# rCSL_emifb_001 register map
Vendor: Texas Instruments
Peripheral module from a debugger description file (folder c674x).
Registers are 32-bit, access not given, reset 0x0 unless marked. A register's access mark holds for its fields unless they carry their own. Offsets are as the file gives them; lines under a group give offsets from that group; [hi:lo] are bit positions; {n}, {i} and the like mark numbered series; 'fields as' and 'values as' point back to an identical list; <NAME> marks a mode.

## EMIFB — This module acts as interface between CPU and SDR SDRAM
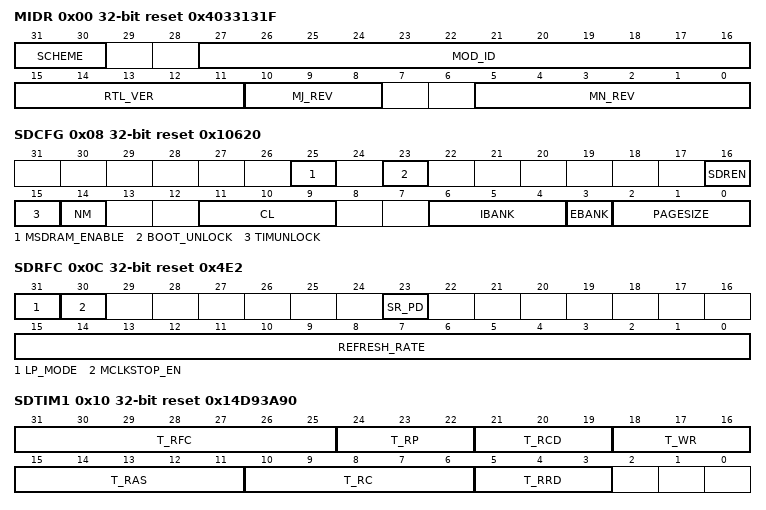
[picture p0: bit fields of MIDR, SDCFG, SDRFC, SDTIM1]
0x00 MIDR reset 0x4033131F — Read only ID register for EMIFB
  [31:30] SCHEME ro — Used to distinguish between old and current schemes
  [27:16] MOD_ID ro — EMIFB module ID
  [15:11] RTL_VER ro — RTL version
  [10:8] MJ_REV ro — Major revision
  [5:0] MN_REV ro — Minor revision
0x08 SDCFG reset 0x10620 — The SDRAM Configuration Register (SDCR) is used to configure various parameters of the SDRAM controller such as the number of internal banks, the internal page size, and the CAS latency to match those of the attached SDRAM device.
  [25] MSDRAM_ENABLE rw — Mobile SDRAM Enable. This bit is writeable only when the BTUNLOCK bit is unlocked. For mobile SDR SDRAM, this bit is only valid when SDREN is set to 1.
    0=MSDR_DIS (When SDREN=1, and this bit is zero, mobile SDR is not enabled.); 1=MSDR_EN (When SDREN=1, and this bit is 1, mobile SDR is enabled.)
  [23] BOOT_UNLOCK rw — Boot unlock. Set to 1 to change the values of the fields that are affected by the BTUNLOCK bit.
    0=BTUN_NOSET (The SDREN bit in this register may not be changed.); 1=BTUN_SET (The SDREN bit in this register may be changed.)
  [16] SDREN rw — SDRAM Enable. Active high bit which enables the SDRAM mode of the EMIF controller. This bit is writeable only when the BTUNLOCK bit is unlocked.
    0=SDR_DISABLE (SDRAM initialization and refreshes disabled, but SDRAM write/read transactions allowed. This bit must not be set to 0 when EMIF is in Self Refresh state.); 1=SDR_ENABLE (SDRAM fully enabled.)
  [15] TIMUNLOCK rw — Timing unlock. Controls the write permission settings for the SDRAM Timing 1 Register and SDRAM Timing 2 Register
    0=TMUN_NOSET (CL in this Register and Register fields in the SDRAM timing 1 register (SDTIMR1) and the SDRAM timing 2 register (SDTIMR2) may not be changed.); 1=TMUN_SET (CL in this Register and Register fields in the SDRAM timing 1 register (SDTIMR1) and the SDRAM timing 2 register (SDTIMR2) may be changed.)
  [14] NM rw — SDRAM data bus width. A write to this field will cause the EMIF to start the SDRAM initialization sequence.
    0=32BIT_SDR (32-bit SDR SDRAM); 1=16BIT_SDR (16-bit SDR SDRAM)
  [11:9] CL rw — CAS latency. A write to this field will cause the EMIF to start the SDRAM initialization sequence. This field is writeable only when the TMUNLOCK bit is unlocked.
  [6:4] IBANK rw — Internal SDRAM Bank setup. Defines number of banks inside connected SDRAM devices. A write to this field will cause the EMIF to start the SDRAM initialization sequence.
  [3] EBANK rw — External chip select setup. Defines whether SDRAM accesses will use 1 or 2 chip select lines. A write to this field will cause the EMIF to start the SDRAM initialization sequence.
    0=CS0 (Use EMIF_CS[0] for all SDRAM accesses.); 1=CS0_AND_CS1 (Use EMIF_CS[0] and EMIF_CS[1] for SDRAM accesses.)
  [2:0] PAGESIZE rw — Page Size. Defines the internal page size of connected SDRAM devices. A write to this field will cause the EMIF to start the SDRAM initialization sequence.
0x0C SDRFC reset 0x4E2 — SDRAM Refresh Control Register
  [31] LP_MODE rw — Low Power mode enable. Writing a 1 to this bit will cause connected SDRAM devices to be place into either Self Refresh or Powerdown mode. The value of SR_PD bit will decide which mode is chosen.
    0=LPMODE (SDRAM placed in self refresh /power down mode depending on the value of SR_PD bit.); 1=NO_LPMODE (SDRAM is NOT to be placed in self refresh/power down mode.)
  [30] MCLKSTOP_EN rw — mclk Stop Enable. Writing a 1 to this bit enables mclk stopping
    0=MCLKSTOP_DIS (mclk stopping disable); 1=MCLKSTOP_EN (mclk stopping enable)
  [23] SR_PD rw — Self Refresh or Powerdown select. Set this bit to 1 to cause connected SDRAM devices to be placed into Powerdown mode. Set this bit to 0 to cause connected SDRAM devices to be placed into Self Refresh mode. This bit is ignored when lp_mode bit is set to 0.
    0=SELF_REFRESH (Connected SDRAM devices placed in self refresh mode); 1=POWER_DOWN (Connected SDRAM devices placed in power down mode)
  [15:0] REFRESH_RATE rw — Refresh Rate. Defines the rate at which connected SDRAM devices will be refreshed.SDRAM refresh rate = EMIFB rate / RR where EMIFB rate is equal to EMIFB SDRAM clock rate. Writing a value < 0x0100 to this field will cause it to be loaded with (2 * t_rfc)+1 value from SDRAM Timing 1 register. The required refresh rate is derived from the SDRAM device data sheet.
0x10 SDTIM1 reset 0x14D93A90 — The SDRAM timing 1 register (SDTIMR1) configures the SDRAM memory controller to meet many of the AC timing specification of the SDRAM memory. The SDTIMR1 register is programmable only when the TMUNLOCK bit is set to 1 in the SDCR. Note that EMB_CLK is equal to the period of the EMB_CLK signal. See the SDRAM memory data sheet for information on the appropriate values to program each field.
  [31:25] T_RFC rw — Specifies the minimum number of EMB_CLK cycles from a refresh or load mode command to a refresh or activate command, minus 1. Corresponds to the trfc AC timing parameter in the SDRAM data sheet. Calculate by: T_RFC = (trfc/EMB_CLK) - 1
  [24:22] T_RP rw — Specifies the minimum number of EMB_CLK cycles from a precharge command to a refresh or activate command, minus 1. Corresponds to the trp AC timing parameter in the SDRAM data sheet. Calculate by: T_RP = (trp/EMB_CLK) - 1
  [21:19] T_RCD rw — Specifies the minimum number of EMB_CLK cycles from an activate command to a read or write command, minus 1. Corresponds to the trcd AC timing parameter in the SDRAM data sheet. Calculate by: T_RCD = (trcd/EMB_CLK) - 1
  [18:16] T_WR rw — Specifies the minimum number of EMB_CLK cycles from the last write transfer to a precharge command, minus 1. Corresponds to the twr AC timing parameter in the SDRAM data sheet. Calculate by: T_WR = (twr/EMB_CLK) - 1 When the value of this field is changed from its previous value, the initialization sequence will begin.
  [15:11] T_RAS rw — Specifies the minimum number of EMB_CLK cycles from an activate command to a precharge command, minus 1. Corresponds to the tras AC timing parameter in the SDRAM data sheet. Calculate by: T_RAS = (tras/EMB_CLK) - 1. T_RAS must be greater than or equal to T_RCD.
  [10:6] T_RC rw — Specifies the minimum number of EMB_CLK cycles from an activate command to an activate command, minus 1. Corresponds to the trc AC timing parameter in the SDRAM data sheet. Calculate by: T_RC = (trc/EMB_CLK) - 1
  [5:3] T_RRD rw — Specifies the minimum number of EMB_CLK cycles from an activate command to an activate command in a different bank, minus 1. Corresponds to the trrd AC timing parameter in the SDRAM data sheet. Calculate by: T_RRD = (trrd/EMB_CLK) - 1 Note: for an 8 bank SDRAM device this field must be equal to ((4 ´ tRRD) + (2 ´ tCK)) / (4 ´ tCK) - 1.
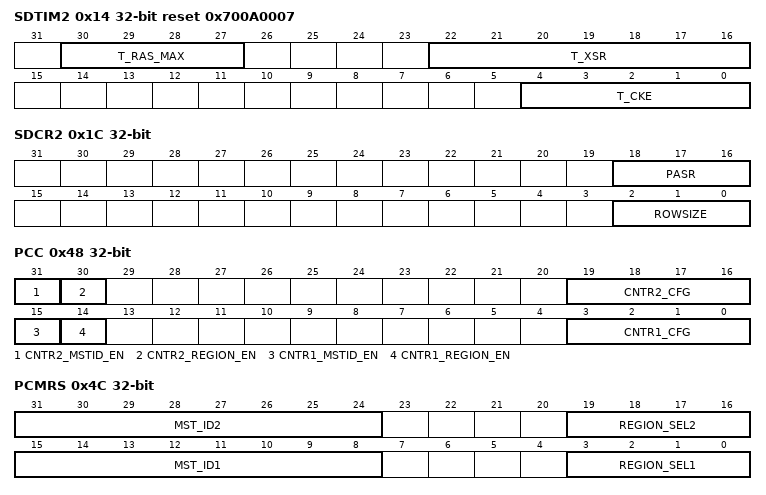
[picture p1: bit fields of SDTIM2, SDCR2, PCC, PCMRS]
0x14 SDTIM2 reset 0x700A0007 — Like the SDRAM timing 1 register (SDTIMR1), the SDRAM timing register 2 (SDTIMR2) also configures the SDRAM memory controller to meet the AC timing specification of the SDRAM memory. The SDTIMR2 register is programmable only when the TIMUNLOCK bit is set to 1 in the SDCR.See the SDRAM data sheet for information on the appropriate values to program each field.
  [30:27] T_RAS_MAX rw — Maximum number of refresh_rate intervals from Activate to Precharge command.
  [22:16] T_XSR rw — Minimum number of EMB_CLK cycles from Self-Refresh exit to any command other than a Read command, minus one. This field must satisfy tXSR for the SDRAM device. T_XSR = txsr*EMIFB_CLK -1
  [4:0] T_CKE rw — Minimum number of EMIFB_CLK cycles between EMB_CKE changes, minus one. This field must satisfy tRAS for the SDRAM device. T_CKE = tras *EMIFB_CLK-1
0x1C SDCR2 — SDRAM Config 2 Register
  [18:16] PASR rw — Partial Array Self Refresh. These bits get loaded into the Extended Mode Register of a mobile SDR or mobile DDR SDRAM during initialization. A write to this field will cause the EMIF to start the SDRAM initialization sequence.
  [2:0] ROWSIZE rw — Row Size. Defines the number of row address bits of connected mobile SDRAM devices. This field is only used when IBANK_POS bit in the SDRAM configuration register (SDCFG) is set to 1. This bit applicable only when EMIFB controller is configured to interface to mobile SDRAM.
0x20 BPRIO reset 0xFF — The peripheral bus burst priority register (PBBPR) helps prevent command starvation within the SDRAM memory controller. To avoid command starvation, the SDRAM memory controller momentarily raises the priority of the oldest command in the command FIFO after a set number of 32 bit transfers have been made on the external memory bus. The PR_OLD_COUNT bit sets the number of transfers that must be made before the SDRAM memory controller raises the priority of the oldest command.
  [7:0] PRIO_RAISE rw — Priority raise old counter. Specifies the number of 32b memory transfers after which the SDRAM memory controller will elevate the priority of the oldest command in the command FIFO. Setting to FFh will disable the feature and setting to 00h will ensure master priority is strictly honored (at the cost of decreased EMIFB efficiency as open row will always be closed immediately if any bank conflict occurs). Recommended setting for typical system operation is between 10h and 20h.
0x40 PC1 ro — For debug or gathering performance statistics, the PC1 and PC2 counters and associated configuration registers are provided. These are intended for debug and analysis only. By configuring the PCC to define the type of statistics to gather and configuring the PCMRS to filter accesses only to specific chip select regions, performing system applications and then reading these counters, different statistics can be gathered. To reset the counters, the user must reset the EMIF module through the PSC.
  [31:0] COUNTER1 — 32-bit counter that can be configured as specified in the performance counter config register and the performance counter master region select register.
0x44 PC2 ro — Performance Counter 2 Register
  [31:0] COUNTER2 — 32-bit counter that can be configured as specified in the performance counter config register and the performance counter master region select register.
0x48 PCC — Performance Counter Config Register
  [31] CNTR2_MSTID_EN rw — Master ID filter enable for performance counter 2 register.
  [30] CNTR2_REGION_EN rw — Chip select filter enable for performance counter 2 register.
  [19:16] CNTR2_CFG rw — Filter configuration for performance counter 2.
  [15] CNTR1_MSTID_EN rw — Master ID filter enable for performance counter 1 register.
  [14] CNTR1_REGION_EN rw — Chip select filter enable for performance counter 1 register.
  [3:0] CNTR1_CFG rw — Filter configuration for performance counter 1.
0x4C PCMRS — Performance Counter Master Region Select Register
  [31:24] MST_ID2 rw — Master ID for performance counter 2 register.
  [19:16] REGION_SEL2 rw — Chip select for performance counter 2 register.
    0=CS0_1 (SDRAM CS0/1); {v}=CS{v+1} (Asynchronous memory CS{v+1}) (v=1..4)
  [15:8] MST_ID1 rw — Master ID for performance counter 1 register.
  [3:0] REGION_SEL1 rw — Chip select for performance counter 1 register.
    values as REGION_SEL2
0x50 PCT ro — Performance Counter Time Register
  [31:0] TOTAL_TIME — 32-bit counter that continuously counts number for SDCLK cycles elapsed after EMIFB is brought out of reset.
0xC0 IRR — The interrupt raw register (IRR) displays the raw status of the interrupt. If the interrupt condition occurs, the corresponding bit in IRR is set independent of whether or not the interrupt is enabled.
  [2] LT rw — Line Trap. Set to 1 by hardware to indicate illegal memory access type. Writing a 1 will clear this bit as well as the LTM bit in the Interrupt Masked register. Writing a 0 has no effect.
    0=RSVD (Indicates that a line trap has not occurred. Writing a 0 has no effect.); 1=CLEAR (Indicates that a line trap has occurred. Writing a 1 will clear this bit and the LTM bit in the EMIF interrupt mask register (EIMR).)
0xC4 IMR — The interrupt masked register (IMR) displays the status of the interrupt when it is enabled. If the interrupt condition occurs and the corresponding bit in the interrupt mask set register (IMSR) is set, then the IMR bit is set. The IMR bit is not set if the interrupt is not enabled in IMSR.
  [2] LTM rw — Masked Line Trap. Set to 1 by hardware to indicate illegal memory access type, only if the LTMSET bit in the Interrupt Mask Set Register is set to 1. Writing a 1 will clear this bit as well as the LT bit in the Interrupt Raw register. Writing a 0 has no effect.
    0=RSVD (Indicates that a line trap interrupt has not been generated. Writing a 0 has no effect.); 1=CLEAR (Indicates that a line trap interrupt has been generated. Writing a 1 will clear this bit and the LT bit in the EMIF interrupt raw register (EIRR).)
0xC8 IMSR — The interrupt mask set register (IMSR) enables the memory controller interrupt.
  [2] LTMSET rw — Mask set for LTM bit in the Interrupt Masked Register. Writing a 1 will enable the interrupt, and set this bit as well as the LTMCLR bit in the Interrupt Mask Clear register. The interrupt will not be enabled, and this bit as well as the LTMCLR bit will not be set if a 1 is written to this bit and the LTMCLR bit at the same time. Writing a 0 has no effect.
    0=RSVD (Indicates that the line trap interrupt is disabled. Writing a 0 has no effect.); 1=SET (Indicates that the line trap interrupt is enabled. Writing a 1 sets this bit and the LTMCLR bit in the EMIF interrupt mask clear register (EIMCR).)
0xCC IMCR — The interrupt mask clear register (IMCR) disables the memory controller interrupt. Once an interrupt is enabled, it may be disabled by writing a 1 to the IMCR bit.
  [2] LTMCLR rw — Mask clear for LTM bit in the Interrupt Masked Register. Writing a 1 will disable the interrupt, and clear this bit as well as the LTMSET bit in the Interrupt Mask Set register. Writing a 0 has no effect.
    0=RSVD (Indicates that the line trap interrupt is disabled. Writing a 0 has no effect.); 1=CLEAR (Indicates that the line trap interrupt is enabled. Writing a 1 clears this bit and the LTMSET bit in them EMIF interrupt mask set register (EIMSR).)
